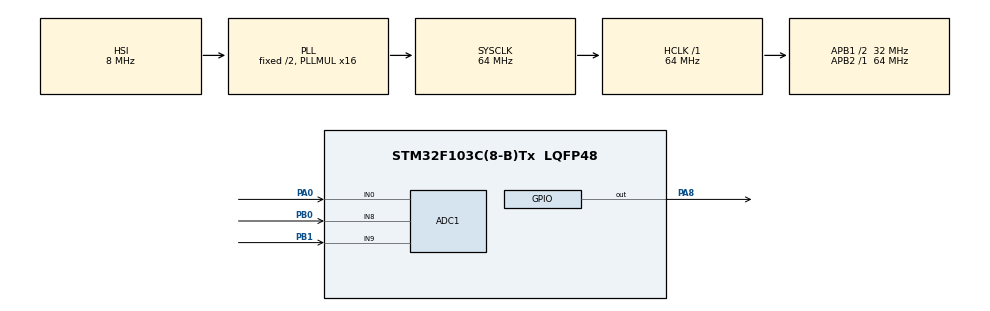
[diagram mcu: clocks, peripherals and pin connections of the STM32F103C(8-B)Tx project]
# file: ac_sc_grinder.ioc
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ADC1.Channel-19\#ChannelRegularConversion=ADC_CHANNEL_9
ADC1.Channel-20\#ChannelRegularConversion=ADC_CHANNEL_8
ADC1.Channel-21\#ChannelRegularConversion=ADC_CHANNEL_0
ADC1.Channel-23\#ChannelRegularConversion=ADC_CHANNEL_VREFINT
ADC1.ContinuousConvMode=ENABLE
ADC1.DataAlign=ADC_DATAALIGN_RIGHT
ADC1.DiscontinuousConvMode=DISABLE
ADC1.EnableAnalogWatchDog=false
ADC1.EnableRegularConversion=ENABLE
ADC1.ExternalTrigConv=ADC_SOFTWARE_START
ADC1.InjNumberOfConversion=0
ADC1.NbrOfConversion=4
ADC1.NbrOfConversionFlag=1
ADC1.Rank-19\#ChannelRegularConversion=1
ADC1.Rank-20\#ChannelRegularConversion=2
ADC1.Rank-21\#ChannelRegularConversion=3
ADC1.Rank-23\#ChannelRegularConversion=4
ADC1.SamplingTime-19\#ChannelRegularConversion=ADC_SAMPLETIME_1CYCLE_5
ADC1.SamplingTime-20\#ChannelRegularConversion=ADC_SAMPLETIME_1CYCLE_5
ADC1.SamplingTime-21\#ChannelRegularConversion=ADC_SAMPLETIME_1CYCLE_5
ADC1.SamplingTime-23\#ChannelRegularConversion=ADC_SAMPLETIME_1CYCLE_5
ADC1.ScanConvMode=ADC_SCAN_ENABLE
ADC1.master=1
Dma.ADC1.0.Direction=DMA_PERIPH_TO_MEMORY
Dma.ADC1.0.Instance=DMA1_Channel1
Dma.ADC1.0.MemDataAlignment=DMA_MDATAALIGN_HALFWORD
Dma.ADC1.0.MemInc=DMA_MINC_ENABLE
Dma.ADC1.0.Mode=DMA_CIRCULAR
Dma.ADC1.0.PeriphDataAlignment=DMA_PDATAALIGN_HALFWORD
Dma.ADC1.0.PeriphInc=DMA_PINC_DISABLE
Dma.ADC1.0.Priority=DMA_PRIORITY_LOW
Dma.Request0=ADC1
Mcu.Family=STM32F1
Mcu.Name=STM32F103C(8-B)Tx
Mcu.Package=LQFP48
NVIC.ADC1_2_IRQn=true\:0\:0\:false\:false\:true\:true
NVIC.DMA1_Channel1_IRQn=true\:0\:0\:false\:false\:true\:true
NVIC.PriorityGroup=NVIC_PRIORITYGROUP_4
PA0-WKUP.Signal=ADCx_IN0
PA13.Mode=Serial_Wire
PA13.Signal=SYS_JTMS-SWDIO
PA14.Mode=Serial_Wire
PA14.Signal=SYS_JTCK-SWCLK
PA8.Signal=GPIO_Output
PB0.Signal=ADCx_IN8
PB1.Signal=ADCx_IN9
ProjectManager.HeapSize=0x200
ProjectManager.StackSize=0x400
ProjectManager.TargetToolchain=Other Toolchains (GPDSC)
RCC.ADCPresc=RCC_ADCPCLK2_DIV8
RCC.AHBFreq_Value=64000000
RCC.APB1CLKDivider=RCC_HCLK_DIV2
RCC.APB1Freq_Value=32000000
RCC.APB1TimFreq_Value=64000000
RCC.APB2Freq_Value=64000000
RCC.APB2TimFreq_Value=64000000
RCC.HCLKFreq_Value=64000000
RCC.PLLMUL=RCC_PLL_MUL16
RCC.SYSCLKFreq_VALUE=64000000
RCC.SYSCLKSource=RCC_SYSCLKSOURCE_PLLCLK
RCC.USBFreq_Value=64000000
SH.ADCx_IN0.0=ADC1_IN0,IN0
SH.ADCx_IN8.0=ADC1_IN8,IN8
SH.ADCx_IN9.0=ADC1_IN9,IN9
VP_ADC1_Vref_Input.Mode=IN-Vrefint
board=ac_sc_grinder

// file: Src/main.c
/**
  ******************************************************************************
  * @file           : main.c
  * @brief          : Main program body
  ******************************************************************************
  ** This notice applies to any and all portions of this file
  * that are not between comment pairs USER CODE BEGIN and
  * USER CODE END. Other portions of this file, whether
  * inserted by the user or by software development tools
  * are owned by their respective copyright owners.
  *
  * COPYRIGHT(c) 2018 STMicroelectronics
  *
  * Redistribution and use in source and binary forms, with or without modification,
  * are permitted provided that the following conditions are met:
  *   1. Redistributions of source code must retain the above copyright notice,
  *      this list of conditions and the following disclaimer.
  *   2. Redistributions in binary form must reproduce the above copyright notice,
  *      this list of conditions and the following disclaimer in the documentation
  *      and/or other materials provided with the distribution.
  *   3. Neither the name of STMicroelectronics nor the names of its contributors
  *      may be used to endorse or promote products derived from this software
  *      without specific prior written permission.
  *
  * THIS SOFTWARE IS PROVIDED BY THE COPYRIGHT HOLDERS AND CONTRIBUTORS "AS IS"
  * AND ANY EXPRESS OR IMPLIED WARRANTIES, INCLUDING, BUT NOT LIMITED TO, THE
  * IMPLIED WARRANTIES OF MERCHANTABILITY AND FITNESS FOR A PARTICULAR PURPOSE ARE
  * DISCLAIMED. IN NO EVENT SHALL THE COPYRIGHT HOLDER OR CONTRIBUTORS BE LIABLE
  * FOR ANY DIRECT, INDIRECT, INCIDENTAL, SPECIAL, EXEMPLARY, OR CONSEQUENTIAL
  * DAMAGES (INCLUDING, BUT NOT LIMITED TO, PROCUREMENT OF SUBSTITUTE GOODS OR
  * SERVICES; LOSS OF USE, DATA, OR PROFITS; OR BUSINESS INTERRUPTION) HOWEVER
  * CAUSED AND ON ANY THEORY OF LIABILITY, WHETHER IN CONTRACT, STRICT LIABILITY,
  * OR TORT (INCLUDING NEGLIGENCE OR OTHERWISE) ARISING IN ANY WAY OUT OF THE USE
  * OF THIS SOFTWARE, EVEN IF ADVISED OF THE POSSIBILITY OF SUCH DAMAGE.
  *
  ******************************************************************************
  */
#include "main.h"
#include "stm32f1xx_hal.h"
#include "adc.h"
#include "dma.h"
#include "gpio.h"

/* USER CODE BEGIN Includes */
#include "../../../src/app.h"
/* USER CODE END Includes */

/* USER CODE BEGIN PV */
/* Private variables ---------------------------------------------------------*/

/* USER CODE END PV */

void SystemClock_Config(void);

/* USER CODE BEGIN PFP */
/* Private function prototypes -----------------------------------------------*/

/* USER CODE END PFP */

int main(void)
{

  /* MCU Configuration----------------------------------------------------------*/

  /* Reset of all peripherals, Initializes the Flash interface and the Systick. */
  HAL_Init();

  /* Configure the system clock */
  SystemClock_Config();

  /* Initialize all configured peripherals */
  MX_GPIO_Init();
  MX_DMA_Init();
  MX_ADC1_Init();
  /* USER CODE BEGIN 2 */
  app_start();
  /* USER CODE END 2 */

  /* Infinite loop */
  while (1)
  {

  }

}

void SystemClock_Config(void)
{

  RCC_OscInitTypeDef RCC_OscInitStruct;
  RCC_ClkInitTypeDef RCC_ClkInitStruct;
  RCC_PeriphCLKInitTypeDef PeriphClkInit;

    /**Initializes the CPU, AHB and APB busses clocks
    */
  RCC_OscInitStruct.OscillatorType = RCC_OSCILLATORTYPE_HSI;
  RCC_OscInitStruct.HSIState = RCC_HSI_ON;
  RCC_OscInitStruct.HSICalibrationValue = 16;
  RCC_OscInitStruct.PLL.PLLState = RCC_PLL_ON;
  RCC_OscInitStruct.PLL.PLLSource = RCC_PLLSOURCE_HSI_DIV2;
  RCC_OscInitStruct.PLL.PLLMUL = RCC_PLL_MUL16;
  if (HAL_RCC_OscConfig(&RCC_OscInitStruct) != HAL_OK)
  {
    _Error_Handler(__FILE__, __LINE__);
  }

    /**Initializes the CPU, AHB and APB busses clocks
    */
  RCC_ClkInitStruct.ClockType = RCC_CLOCKTYPE_HCLK|RCC_CLOCKTYPE_SYSCLK
                              |RCC_CLOCKTYPE_PCLK1|RCC_CLOCKTYPE_PCLK2;
  RCC_ClkInitStruct.SYSCLKSource = RCC_SYSCLKSOURCE_PLLCLK;
  RCC_ClkInitStruct.AHBCLKDivider = RCC_SYSCLK_DIV1;
  RCC_ClkInitStruct.APB1CLKDivider = RCC_HCLK_DIV2;
  RCC_ClkInitStruct.APB2CLKDivider = RCC_HCLK_DIV1;

  if (HAL_RCC_ClockConfig(&RCC_ClkInitStruct, FLASH_LATENCY_2) != HAL_OK)
  {
    _Error_Handler(__FILE__, __LINE__);
  }

  PeriphClkInit.PeriphClockSelection = RCC_PERIPHCLK_ADC;
  PeriphClkInit.AdcClockSelection = RCC_ADCPCLK2_DIV8;
  if (HAL_RCCEx_PeriphCLKConfig(&PeriphClkInit) != HAL_OK)
  {
    _Error_Handler(__FILE__, __LINE__);
  }

    /**Configure the Systick interrupt time
    */
  HAL_SYSTICK_Config(HAL_RCC_GetHCLKFreq()/1000);

    /**Configure the Systick
    */
  HAL_SYSTICK_CLKSourceConfig(SYSTICK_CLKSOURCE_HCLK);

  /* SysTick_IRQn interrupt configuration */
  HAL_NVIC_SetPriority(SysTick_IRQn, 0, 0);
}

void _Error_Handler(char *file, int line)
{
  /* USER CODE BEGIN Error_Handler_Debug */
  (void)(file);
  (void)(line);
  /* User can add his own implementation to report the HAL error return state */
  while(1)
  {
  }
  /* USER CODE END Error_Handler_Debug */
}

/************************ (C) COPYRIGHT STMicroelectronics *****END OF FILE****/
